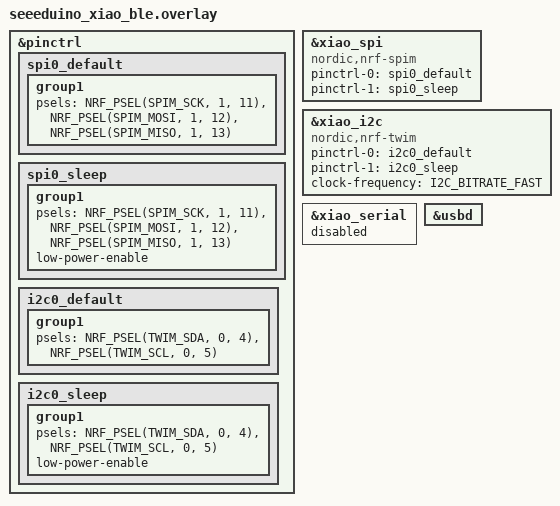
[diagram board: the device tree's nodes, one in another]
/*
 * Copyright (c) 2024 Shota Nishide
 * SPDX-License-Identifier: MIT
 */

&pinctrl {
    spi0_default: spi0_default {
        group1 {
            psels = <NRF_PSEL(SPIM_SCK, 1, 11)>,
                    <NRF_PSEL(SPIM_MOSI, 1, 12)>,
                    <NRF_PSEL(SPIM_MISO, 1, 13)>;
        };
    };

    spi0_sleep: spi0_sleep {
        group1 {
            psels = <NRF_PSEL(SPIM_SCK, 1, 11)>,
                    <NRF_PSEL(SPIM_MOSI, 1, 12)>,
                    <NRF_PSEL(SPIM_MISO, 1, 13)>;
            low-power-enable;
        };
    };

    i2c0_default: i2c0_default {
        group1 {
            psels = <NRF_PSEL(TWIM_SDA, 0, 4)>,
                    <NRF_PSEL(TWIM_SCL, 0, 5)>;
        };
    };

    i2c0_sleep: i2c0_sleep {
        group1 {
            psels = <NRF_PSEL(TWIM_SDA, 0, 4)>,
                    <NRF_PSEL(TWIM_SCL, 0, 5)>;
            low-power-enable;
        };
    };
};

&xiao_spi {
    status = "okay";
    compatible = "nordic,nrf-spim";
    pinctrl-0 = <&spi0_default>;
    pinctrl-1 = <&spi0_sleep>;
    pinctrl-names = "default", "sleep";
};

&xiao_i2c {
    status = "okay";
    compatible = "nordic,nrf-twim";
    pinctrl-0 = <&i2c0_default>;
    pinctrl-1 = <&i2c0_sleep>;
    pinctrl-names = "default", "sleep";
    clock-frequency = <I2C_BITRATE_FAST>;
};

// Disable serial to free up pins
&xiao_serial { 
    status = "disabled"; 
};

// Enable USB
&usbd {
    status = "okay";
};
